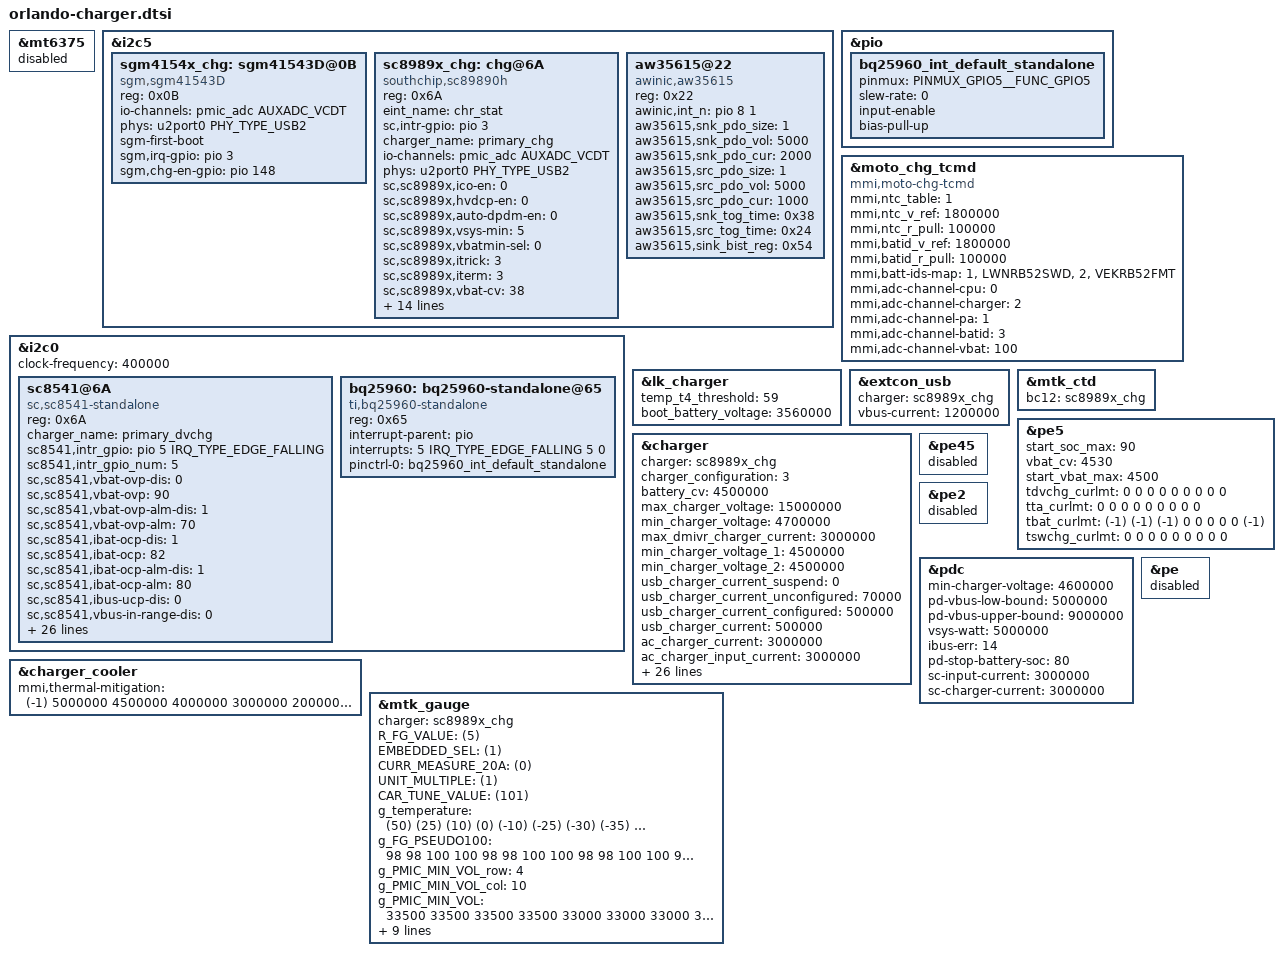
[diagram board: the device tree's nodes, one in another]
/*
 * Copyright (c) 2025 MediaTek Inc.
 *
 * This program is free software; you can redistribute it and/or modify
 * it under the terms of the GNU General Public License version 2 as
 * published by the Free Software Foundation.
 *
 * This program is distributed in the hope that it will be useful,
 * but WITHOUT ANY WARRANTY; without even the implied warranty of
 * MERCHANTABILITY or FITNESS FOR A PARTICULAR PURPOSE.  See the
 * GNU General Public License for more details.
 */
#include <dt-bindings/iio/mt635x-auxadc.h>

&mt6375 {
	status = "disabled";
};

&i2c5 {
	sgm4154x_chg: sgm41543D@0B {
		status = "okay";
		compatible = "sgm,sgm41543D";
		reg = <0x0B>;
		io-channels = <&pmic_adc AUXADC_VCDT>;
		io-channel-names = "pmic_vbus";
 		phys = <&u2port0 PHY_TYPE_USB2>;
 		phy-names = "usb2-phy";
		sgm-first-boot;
		sgm,irq-gpio = <&pio 3 IRQ_TYPE_EDGE_FALLING>;     //irq num base on hardware design
		sgm,chg-en-gpio = <&pio 148 0>;   //gpio num base on hardware design  1.MTK parent node name is pio  2.QUALCOMM parent node name is tlmm or other
	};
	sc8989x_chg: chg@6A {
		compatible = "southchip,sc89890h";
		reg = <0x6A>;
		status = "okay";
		eint_name = "chr_stat";
		sc,intr-gpio = <&pio 3 IRQ_TYPE_EDGE_FALLING>;
		charger_name = "primary_chg";
		io-channels = <&pmic_adc AUXADC_VCDT>;
		io-channel-names = "pmic_vbus";
		phys = <&u2port0 PHY_TYPE_USB2>;
		phy-names = "usb2-phy";
		sc,sc8989x,ico-en = <0>;
		sc,sc8989x,hvdcp-en = <0>;
		sc,sc8989x,auto-dpdm-en = <0>;
		sc,sc8989x,vsys-min = <5>; /*3500mV*/
		sc,sc8989x,vbatmin-sel = <0>; /*0:2.9V 1:2.5V*/
		sc,sc8989x,itrick = <3>; /*60 + val *60*/
		sc,sc8989x,iterm = <3>; /*30 + val * 60*/
		sc,sc8989x,vbat-cv = <38>; /*3840 + val * 16*/
		sc,sc8989x,vbat-low = <1>; /*0:2.8V 1:3V*/
		sc,sc8989x,vrechg = <0>; /*0:100mV 1:200mV*/
		sc,sc8989x,en-term = <1>;
		sc,sc8989x,stat-dis = <0>;
		sc,sc8989x,wd-time = <0>; /*0:Dis 1:40s 2:80s 3:160s*/
		sc,sc8989x,en-timer = <1>;
		sc,sc8989x,charge-timer = <2>; /*0:5h 1:8h 2:12h 3:20h*/
		sc,sc8989x,bat-comp = <0>; /*val * 20*/
		sc,sc8989x,vclamp = <0>; /*val *32*/
		sc,sc8989x,votg = <12>; /*3900 + val * 100*/
		sc,sc8989x,iboost = <7>; /*0:0.5A 3:1.4A 5:1.875A 7:2.45A*/
		sc,sc8989x,force_vindpm = <0>;
		sc,sc8989x,vindpm = <18>; /*2600 + val * 100*/
		sc,vindpm-track = <3>; /*0: DIS 1:200, 2:250 3:300*/
	};
        aw35615@22 {
                compatible = "awinic,aw35615";
                reg = <0x22>;
                status = "okay";
                awinic,int_n = <&pio 8 1>;
                aw35615,snk_pdo_size = <1>; /* set sink pdo num*/
                aw35615,snk_pdo_vol = <5000>; /* set sink pdo voltage mV*/
                aw35615,snk_pdo_cur = <2000>; /* set sink pdo current mA*/
                aw35615,src_pdo_size = <1>; /* set source pdo num*/
                aw35615,src_pdo_vol = <5000>; /* set source pdo voltage mV*/
                aw35615,src_pdo_cur = <1000>; /* set source pdo current mA*/
                aw35615,snk_tog_time = <0x38>; /* set toggle sink time */
                aw35615,src_tog_time = <0x24>; /* set toggle source time */
                aw35615,sink_bist_reg = <0x54>; /* set MDAC reg 0x50*/
        };
};

&pio {
       bq25960_int_default_standalone: bq25960_int_default_standalone {
               pinmux = <PINMUX_GPIO5__FUNC_GPIO5>;
               slew-rate= <0>;
               input-enable;
               bias-pull-up;
       };
};

&i2c0 {
	clock-frequency = <400000>;
	sc8541@6A {
		compatible = "sc,sc8541-standalone";
		reg = <0x6A>;
		charger_name = "primary_dvchg";
		sc8541,intr_gpio = <&pio 5 IRQ_TYPE_EDGE_FALLING>;
		sc8541,intr_gpio_num = <5>;
		sc,sc8541,vbat-ovp-dis = <0>;
		sc,sc8541,vbat-ovp = <90>; /*3840 + val * 10*/
		sc,sc8541,vbat-ovp-alm-dis = <1>;
		sc,sc8541,vbat-ovp-alm = <70>; /*3840 + val * 10*/
		sc,sc8541,ibat-ocp-dis = <1>;
		sc,sc8541,ibat-ocp  = <82>; /*val * 100*/
		sc,sc8541,ibat-ocp-alm-dis = <1>;
		sc,sc8541,ibat-ocp-alm = <80>; /*val * 100*/
		sc,sc8541,ibus-ucp-dis = <0>;
		sc,sc8541,vbus-in-range-dis = <0>;
		sc,sc8541,vbus-pd-en = <0>;
		sc,sc8541,vbus-ovp = <80>; /*7000 + val * 50*/
		sc,sc8541,vbus-ovp-alm-dis = <1>;
		sc,sc8541,vbus-ovp-alm = <34>; /*7000 + val * 50*/
		sc,sc8541,ibus-ocp-dis = <0>;
		sc,sc8541,ibus-ocp = <13>; /*1000 + val * 250*/
		sc,sc8541,tshut-dis = <1>;
		sc,sc8541,tsbus-flt-dis = <1>;
		sc,sc8541,tsbat-flt-dis = <1>;
		sc,sc8541,tdie-alm = <200>; /*25 + val * 0.5*/
		sc,sc8541,tsbus-flt = <21>;
		sc,sc8541,tsbat-flt = <21>;
		sc,sc8541,vac1-ovp = <2>; /*0:6.5V 1:10.5V 2:12V 3:14V 4:16V 5~7:18V*/
		sc,sc8541,vac2-ovp = <3>; /*0:6.5V 1:10.5V 2:12V 3:14V 4:16V 5~7:18V*/
		sc,sc8541,vac1-pd-en = <0>;
		sc,sc8541,vac2-pd-en = <0>;
		sc,sc8541,fsw-set = <5>; /*0:200KHz 1:300KHz 2:400KHz
					3:500KHz 4:600KHz 5:650KHz 6:700KHz 7:750KHz*/
		sc,sc8541,wd-timeout = <0>; /*0:0.5s 1:1s 2:5s 3:30s*/
		sc,sc8541,wd-timeout-dis = <1>;
		sc,sc8541,ibat-sns-r = <0>; /*0:2mho 1:5mho*/
		sc,sc8541,ss-timeout = <7>; /*0:6.25ms 1:12.5ms 2:25ms 3:50ms
					4:100ms 5:400ms 6:1.5s 7:10s*/
		sc,sc8541,ibus-ucp-fall-dg = <1>;
		sc,sc8541,vout-ovp-dis = <0>;
		sc,sc8541,vout-ovp = <3>; /*4700 + val * 100*/
		sc,sc8541,pmid2out-uvp = <7>; /*50 + val * 25*/
		sc,sc8541,pmid2out-ovp = <7>; /*150 + val * 50*/
	};

	bq25960:bq25960-standalone@65 {
		status = "okay";
		compatible = "ti,bq25960-standalone";
		reg = <0x65>;

		interrupt-parent = <&pio>;
		interrupts = <5 IRQ_TYPE_EDGE_FALLING 5 0>;
		interrupt-names = "bq25960_irq_standalone";

		pinctrl-names = "default";
		pinctrl-0 = <&bq25960_int_default_standalone>;
	};
};

&moto_chg_tcmd {
                compatible = "mmi,moto-chg-tcmd";
                status = "okay";

                mmi,ntc_table = <1>;
                mmi,ntc_v_ref = <1800000>;
                mmi,ntc_r_pull = <100000>;

                mmi,batid_v_ref = <1800000>;
                mmi,batid_r_pull = <100000>;
                mmi,batt-ids-map = "1", "LWNRB52SWD", "2", "VEKRB52FMT";
                mmi,adc-channel-cpu = <0>;
                mmi,adc-channel-charger = <2>;
                mmi,adc-channel-pa = <1>;
                mmi,adc-channel-batid = <3>;
                mmi,adc-channel-vbat = <100>;
};

&lk_charger {
        temp_t4_threshold = <59>;
        boot_battery_voltage = <3560000>;
};

&extcon_usb {
	charger = <&sc8989x_chg>;
	vbus-current = <1200000>;
};

&mtk_ctd {
	bc12 = <&sc8989x_chg>;
};
&charger {
         charger = <&sc8989x_chg>;
         charger_configuration= <3>;
         /* common */
         battery_cv = <4500000>;
         max_charger_voltage = <15000000>;
         min_charger_voltage = <4700000>;
         max_dmivr_charger_current = <3000000>;
         min_charger_voltage_1 = <4500000>;
         min_charger_voltage_2 = <4500000>;

         //enable_pe_plus;
         //enable_sw_jeita;

         /* charging current */
         usb_charger_current_suspend = <0>;
         usb_charger_current_unconfigured = <70000>;
         usb_charger_current_configured = <500000>;
         usb_charger_current = <500000>;
         ac_charger_current = <3000000>;
         ac_charger_input_current = <3000000>;
         non_std_ac_charger_current = <1000000>;
         charging_host_charger_current = <1500000>;
         apple_1_0a_charger_current = <650000>;
         apple_2_1a_charger_current = <800000>;
         ta_ac_charger_current = <3600000>;
         typec_limit_aicr = <3000000>;

         /* PE */
         ta_ac_9v_input_current = <2000000>;
         ta_ac_7v_input_current = <2000000>;

         //mmi config
         mmi,iterm-ma = <280>;
         mmi,mmi-temp-zones =
                        <0 4200 1000  0>,
                        <10 4250 2500 1530>,
                        <15 4500 2500 2500>,
                        <45 4320 5800 5200>,
                        <45 4450 5200 4000>,
                        <60 4200 2500 0>;

	mmi,mmi-ffc-zones = <0 4200 280>,
			<10 4500 280>,
			<15 4500 280>,
			<25 4530 717>,
			<35 4530 805>,
			<45 4530 1167>,
			<60 4200 280>;

	mmi,mmi-normal-zones = <0 4200 280>,
			<10 4500 280>,
			<15 4500 280>,
			<25 4500 280>,
			<35 4500 280>,
			<45 4500 535>,
			<60 4200 280>;

         mmi,enable-charging-limit;
         mmi,upper-limit-capacity = <65>;
         mmi,lower-limit-capacity = <60>;
         mmi,vfloat-comp-uv = <0>;
         mmi,enable-mux;
         fast_charging_indicator = <0x14>;
         mmi,power-max-design-mw = <30000>;
};

&pe5 {
	start_soc_max = <90>;
	vbat_cv = <4530>;
	start_vbat_max = <4500>;
	tdvchg_curlmt = <0 0 0 0 0 0 0 0 0>;
	tta_curlmt = <0 0 0 0 0 0 0 0 0>;
	tbat_curlmt = <(-1) (-1) (-1) 0 0 0 0 0 (-1)>;
	tswchg_curlmt = <0 0 0 0 0 0 0 0 0>;
};

&pe45 {
	status = "disabled";
};

&pe2 {
	status = "disabled";
};

&pdc {
         min-charger-voltage = <4600000>;
         pd-vbus-low-bound = <5000000>;
         pd-vbus-upper-bound = <9000000>;
         vsys-watt = <5000000>;
         ibus-err = <14>;

         pd-stop-battery-soc = <80>;

         /* single charger */
         sc-input-current = <3000000>;
         sc-charger-current = <3000000>;
};

&pe {
	status = "disabled";
};

&charger_cooler {
       mmi,thermal-mitigation = <(-1) 5000000 4500000 4000000 3000000
                               2000000 1000000 600000 500000>;
};

&mtk_gauge {
	charger = <&sc8989x_chg>;
	R_FG_VALUE = <(5)>; /*R_sense resistance*/
	EMBEDDED_SEL = <(1)>;
	CURR_MEASURE_20A = <(0)>;
	UNIT_MULTIPLE = <(1)>;
	CAR_TUNE_VALUE = <(101)>;

	/* battery prop */
	g_temperature = <(50) (25) (10) (0) (-10) (-25) (-30) (-35) (-40) (-45)>;
	g_FG_PSEUDO100 = <98 98 100 100
		98 98 100 100
		98 98 100 100
		98 98 100 100
		98 98 100 100
		100 100 100 100
		100 100 100 100
		100 100 100 100
		100 100 100 100
		100 100 100 100>;
	/*vboot voltage for gauge 0%*/
	g_PMIC_MIN_VOL_row = <4>;
	g_PMIC_MIN_VOL_col = <10>;
	g_PMIC_MIN_VOL = <33500  33500  33500  33500
		33000  33000  33000  33000
		33000  33000  33000  33000
		32200  32200  32200  32200
		30000  30000  30000  30000
		30000  30000  30000  30000
		30000  30000  30000  30000
		30000  30000  30000  30000
		30000  30000  30000  30000
		30000  30000  30000  30000>;
	/*Pseudo1 hide percentage*/
	g_QMAX_SYS_VOL_row = <4>;
	g_QMAX_SYS_VOL_col = <10>;
	g_QMAX_SYS_VOL = <34950  34950  34950  34950
		34950  34950  34950  34950
		34250  34250  34250  34250
		34250  34250  34250  34250
		33500  33500  33500  33500
		32500  32500  32500  32500
		32500  32500  32500  32500
		32500  32500  32500  32500
		32500  32500  32500  32500
		32500  32500  32500  32500>;

	g_Q_MAX = <5130 5122 4996 4996
		5230 5168 4996 4996
		5183 5165 4996 4996
		5101 5096 4996 4996
		4916 4984 4996 4996
		4990 4996 4996 4996
		4990 4996 4996 4996
		4990 4996 4996 4996
		4990 4996 4996 4996
		4990 4996 4996 4996>;

	g_Q_MAX_H_CURRENT = <5117 5106 4990 4990
		5213 5155 4990 4990
		5106 5108 4990 4990
		4861 4898 4990 4990
		4389 4361 4990 4990
		4970 4990 4990 4990
		4970 4990 4990 4990
		4970 4990 4990 4990
		4970 4990 4990 4990
		4970 4990 4990 4990>;

	df-serialnum = "LWNRB52SWD";
	#include "bat_setting/mt6835_battery_rb52_swd_5200mah.dtsi"
	#include "bat_setting/mt6835_battery_rb52_fmt_5200mah.dtsi"
};

